# cslr_vcp2_config_bus register map
Vendor: Texas Instruments
Peripheral module from a debugger description file.
Registers are 32-bit, access per field, reset 0x0 unless marked. A register's access mark holds for its fields unless they carry their own. Offsets are as the file gives them; lines under a group give offsets from that group; [hi:lo] are bit positions; {n}, {i} and the like mark numbered series; 'fields as' and 'values as' point back to an identical list; <NAME> marks a mode.

## VCP2 — Viterbi Coprocessor 2 (VCP2) is a programmable peripheral for decoding of convolutional codes, integrated into Texas Instruments' Himalaya DSP device
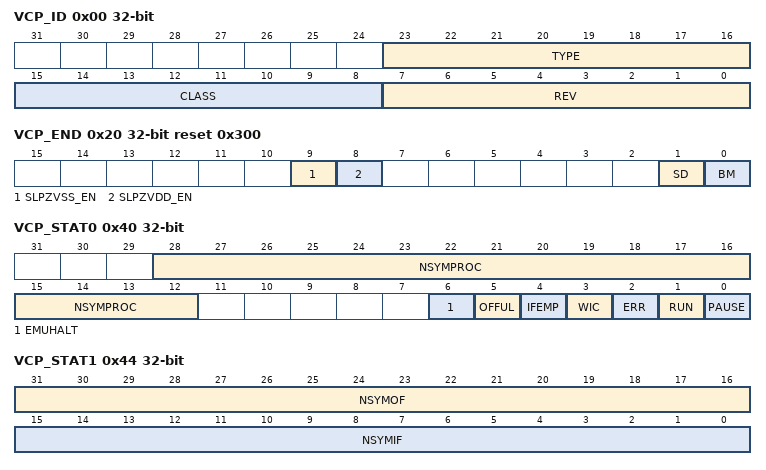
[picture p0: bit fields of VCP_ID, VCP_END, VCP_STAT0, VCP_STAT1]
0x00 VCP_ID ro — VCP Peripheral ID Register
  [23:16] TYPE — Peripheral Type.
  [15:8] CLASS — Peripheral Class.
  [7:0] REV — Peripheral revision.
0x18 VCP_EXE — VCP Execution register
  [3:0] COMMAND wo — VCP Command select bits.
    0=NOCMD (Reserved. (No instruction)); 1=START (Start VCP (Normal mode)); 2=PAUSE (Halt or Pause VCP (debug mode). The VCP is halted (or paused) after processing the state metrics for the current sliding window and before the start of the traceback); 3=RESTART_PAUSE (Restart VCP and process one SW (debug mode). The VCP is restarted from the pause state and begins the traceback operation. The VCP is again paused after processing the state metrics for next sliding window.); 4=RESTART (Restart VCP (debug mode). The VCP is restarted from the paused state and begins the traceback operation. The VCP will run to normal completion); 5=STOP (Stop. Soft reset all VCP registers to their initial condition. All registers in the VCP are reset in this mode except for the execution register, endian register, emulation register and other internal registers)
0x20 VCP_END rw reset 0x300 — VCP Endian mode register
  [9] SLPZVSS_EN — Power down control bits.
    0=SLEEP_DIS (Disable sleep mode); 1=SLPVSS_EN (Enable internal control of slpzvss)
  [8] SLPZVDD_EN — Power down control bits.
    0=SLEEP_DIS (Disable sleep mode); 1=SLPVDD_EN (Enable internal control of slpzvdd)
  [1] SD — Soft Decision memory format select bits.
    0=32BIT (32-bit-word packed); 1=NATIVE (Native format (8 bits))
  [0] BM — Branch Metrics memory format select bits.
    values as SD
0x40 VCP_STAT0 — VCP Status register 0
  [28:12] NSYMPROC ro — Bits indicating number of symbols processed .
  [6] EMUHALT ro — Emulation halt status bit.
    0=NO (Not halt due to emulation); 1=YES (Halt due to emulation)
  [5] OFFUL ro — Output FIFO buffer full status bits.
    0=NO (Output FIFO buffer not full); 1=YES (Output FIFO buffer full)
  [4] IFEMP ro — Input FIFO buffer empty status bits.
    0=NO (Input FIFO buffer is not empty); 1=YES (Input FIFO buffer is empty)
  [3] WIC ro — Bit indicating VCP wait status for input configuration words.
    0=NO (Not waiting for input configuration words); 1=YES (Waiting for input configuration words)
  [2] ERR ro — VCP error status bit.
    0=NO (No error); 1=YES (VCP paused due to error)
  [1] RUN ro — VCP running status bit.
    0=NO (VCP is not running); 1=YES (VCP is running)
  [0] PAUSE ro — VCP Pause status bit.
    0=NO (VCP is not paused); 1=YES (VCP is paused)
0x44 VCP_STAT1 ro — VCP Status register 1
  [31:16] NSYMOF — Number of symbols in the output FIFO buffer.
  [15:0] NSYMIF — Number of symbols in Branch metrics input FIFO buffer.
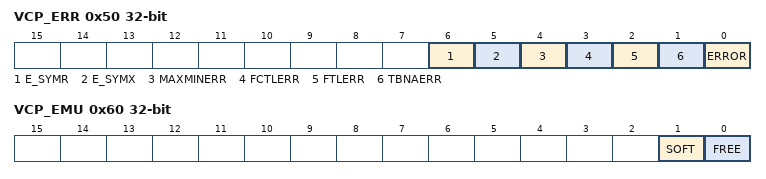
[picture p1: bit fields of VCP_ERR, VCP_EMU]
0x50 VCP_ERR — VCP Error register
  [all] fields
    0=NO (No error); 1=YES
  [6] E_SYMR ro — Bit indicating SYMR erorr.
  [5] E_SYMX ro — Bit indicating SYMX error.
  [4] MAXMINERR ro — Bit indicating error due to invalid maximum and minimum initial state metric.
  [3] FCTLERR ro — Bit indicating error when the sum of reliability length and convergent distance is greater than the maximum allowed .
  [2] FTLERR ro — Bit indicating error when frame length is greater than the maximum in the tailed traceback mode.
  [1] TBNAERR ro — Bit indicating error when invalied Traceback mode is used.
  [0] ERROR ro — Error bit.
0x60 VCP_EMU rw — VCP Emulation control register
  [1] SOFT — This bit controls the behavior of VCP during CPU emulation halt if FREE bit=1.
    0=HALT_DEFAULT (The VCP is halted (or paused) after processing the state metrics for the current sliding window and before the start of the traceback or at the end of a frame.); 1=HALT_FRAMEEND (The VCP is halted (or paused) after processing the ongoing frame.)
  [0] FREE — This bit determines the emulation operation.
    0=SOFT_EN (SOFT bit controls emulation during emulation halt.); 1=FREE (Emulation Halt has no effect on VCP operation.)
